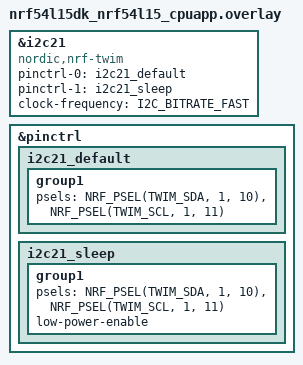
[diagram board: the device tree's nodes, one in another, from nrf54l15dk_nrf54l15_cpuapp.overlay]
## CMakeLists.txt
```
cmake_minimum_required(VERSION 3.20.0)
find_package(Zephyr REQUIRED HINTS $ENV{ZEPHYR_BASE})

project(SCIeval)

target_sources(app PRIVATE
  src/main.c
  src/myble.c
  src/mygpio.c
  src/mysci.c
)

zephyr_library_include_directories(.)
```

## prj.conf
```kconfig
# ==============================
# Logging / Console
# ==============================
CONFIG_LOG=y
CONFIG_LOG_DEFAULT_LEVEL=3

CONFIG_SERIAL=y
CONFIG_UART_CONSOLE=y

# スタック余裕（ログやBLE処理のため）
CONFIG_MAIN_STACK_SIZE=2048
CONFIG_SYSTEM_WORKQUEUE_STACK_SIZE=2048

# ==============================
# Bluetooth (Peripheral/Server)
# ==============================
CONFIG_BT=y
CONFIG_BT_PERIPHERAL=y
# CONFIG_BT_GATT_SERVER は存在しないため指定不要（Peripheralで自動的にGATTサーバ有効）

# デバイス名（Central側が検索する名前に合わせる）
CONFIG_BT_DEVICE_NAME="0514_Test_peripheral"
CONFIG_BT_DEVICE_APPEARANCE=0

# 接続数（必要に応じて調整）
CONFIG_BT_MAX_CONN=1
CONFIG_BT_MAX_PAIRED=1

# ==============================
# PHY / Data Length / MTU
# ==============================
# 2M PHY（ホスト側手続きとコントローラの2M対応）
CONFIG_BT_PHY_UPDATE=y
CONFIG_BT_CTLR_PHY_2M=y

# Data Length Update（bt_conn_le_data_len_update() を使う）
CONFIG_BT_DATA_LEN_UPDATE=y

# ATT MTU（L2CAP TX MTUはMTUに依存）
CONFIG_BT_ATT_PREPARE_COUNT=0
CONFIG_BT_L2CAP_TX_MTU=247

# ACLバッファはデフォルトを使用する
# ※以下のようなシンボルは環境によって未定義のため設定しない
# CONFIG_BT_BUF_ACL_TX_SIZE=
# CONFIG_BT_BUF_ACL_RX_SIZE=
# CONFIG_BT_BUF_ACL_TX_COUNT=
# CONFIG_BT_BUF_ACL_RX_COUNT=

# ==============================
# Nordic LED Button Service (LBS)
# ==============================
CONFIG_BT_LBS=y

# ==============================
# Security（任意）
# ==============================
CONFIG_BT_SMP=n

# ==============================
# その他（必要に応じて）
# ==============================
# GPIOドライバ等はボード定義で有効になっています
```

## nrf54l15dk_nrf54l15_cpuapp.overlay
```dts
/* I2C設定: TWIM21を使用（UART20との競合回避） */

&i2c21 {
    status = "okay";
    compatible = "nordic,nrf-twim";
    pinctrl-0 = <&i2c21_default>;
    pinctrl-1 = <&i2c21_sleep>;
    pinctrl-names = "default", "sleep";
    //clock-frequency = <I2C_BITRATE_STANDARD>; /* 100kHz */
    clock-frequency = <I2C_BITRATE_FAST>; /* 400kHz */
    //clock-frequency = <I2C_BITRATE_FAST_PLUS>; /* 1MHz */
};

&pinctrl {
    i2c21_default: i2c21_default {
        group1 {
            psels = <NRF_PSEL(TWIM_SDA, 1, 10)>,
                    <NRF_PSEL(TWIM_SCL, 1, 11)>;
            //bias-pull-up;  /* ★ 内蔵プルアップを有効化 */
        };
    };

    i2c21_sleep: i2c21_sleep {
        group1 {
            psels = <NRF_PSEL(TWIM_SDA, 1, 10)>,
                    <NRF_PSEL(TWIM_SCL, 1, 11)>;
            low-power-enable;
            //bias-pull-up;  /* ★ スリープ時もプルアップを維持 */
        };
    };
};
```

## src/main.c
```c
#include <zephyr/kernel.h>
#include <zephyr/sys/util.h>
#include <zephyr/sys/atomic.h>
#include <zephyr/logging/log.h>
#include <zephyr/bluetooth/bluetooth.h>
#include <zephyr/bluetooth/conn.h>
#include <zephyr/bluetooth/hci.h>
#include <zephyr/bluetooth/gatt.h>
#include <bluetooth/services/lbs.h>
#include <stdio.h>
#include <string.h>

#include "mygpio.h"
#include "myble.h"
#include "mysci.h"

#define DK //DK or XIAO

LOG_MODULE_REGISTER(blinky, LOG_LEVEL_INF);

#define RUN_LED_BLINK_INTERVAL 1000

/* ======== BTN2押下状態（mygpio.c から更新される） ======== */
atomic_t btn2_pressed_atomic = ATOMIC_INIT(0);

/* ======== カスタムGATT（Notifyで1バイト値を送る） ======== */
/* 任意の128-bit Vendor UUID（アプリ側と合わせればOK） */
static struct bt_uuid_128 casio_svc_uuid = BT_UUID_INIT_128(
    0xF0,0xDE,0xBC,0x9A,0x78,0x56,0x34,0x12,0x34,0x12,0x78,0x56,0x34,0x12,0x56,0x12);
static struct bt_uuid_128 casio_chr_uuid = BT_UUID_INIT_128(
    0xF1,0xDE,0xBC,0x9A,0x78,0x56,0x34,0x12,0x34,0x12,0x78,0x56,0x34,0x12,0x56,0x12);

static uint8_t casio_last_value = 0;
static uint8_t casio_notify_enabled = 0;

/* 送信完了のバックプレッシャ制御（1本インフライト） */
static K_SEM_DEFINE(notify_sem, 1, 1);
static struct bt_gatt_notify_params casio_notify_params;

static void casio_ccc_cfg_changed(const struct bt_gatt_attr *attr, uint16_t value) {
    casio_notify_enabled = (value == BT_GATT_CCC_NOTIFY) ? 1 : 0;
}

static ssize_t casio_read(struct bt_conn *conn, const struct bt_gatt_attr *attr,
                          void *buf, uint16_t len, uint16_t offset) {
    const uint8_t *val = &casio_last_value;
    return bt_gatt_attr_read(conn, attr, buf, len, offset, val, sizeof(*val));
}

/* 静的サービス定義: [0]=Primary, [1]=Char Decl, [2]=Char Value, [3]=CCC */
BT_GATT_SERVICE_DEFINE(casio_svc,
    BT_GATT_PRIMARY_SERVICE(&casio_svc_uuid),
    BT_GATT_CHARACTERISTIC(&casio_chr_uuid.uuid,
        BT_GATT_CHRC_READ | BT_GATT_CHRC_NOTIFY,
        BT_GATT_PERM_READ, casio_read, NULL, &casio_last_value),
    BT_GATT_CCC(casio_ccc_cfg_changed, BT_GATT_PERM_READ | BT_GATT_PERM_WRITE)
);

/* ======== 周期送信ワーク（BTN2押下中のみ送信） ======== */
#define BTN2_TX_INTERVAL_MS 1
static struct k_work_delayable btn2_stream_work;

/* notify 完了コールバック：セマフォを返し、押下中は即次弾を起動 */
static void notify_complete_cb(struct bt_conn *conn, void *user_data)
{
    ARG_UNUSED(conn);
    ARG_UNUSED(user_data);
    k_sem_give(&notify_sem);

    if (atomic_get(&btn2_pressed_atomic) && ble_ready && (my_conn != NULL) && casio_notify_enabled) {
        /* 可能であれば次の送信を即実行（遅延を最小化） */
        k_work_reschedule(&btn2_stream_work, K_NO_WAIT);
    }
}

/* 値を通知する（1本だけインフライト許可） */
static int casio_notify_u8(uint8_t v) {
    if (!ble_ready || my_conn == NULL || !casio_notify_enabled) {
        return -EAGAIN;
    }

    /* インフライトがある場合はスキップ（次のタイミングへ） */
    if (k_sem_take(&notify_sem, K_NO_WAIT) != 0) {
        return -EAGAIN;
    }

    casio_last_value = v;

    memset(&casio_notify_params, 0, sizeof(casio_notify_params));
    casio_notify_params.attr = &casio_svc.attrs[2]; /* Characteristic Value */
    casio_notify_params.data = &casio_last_value;
    casio_notify_params.len  = sizeof(casio_last_value);
    casio_notify_params.func = notify_complete_cb;

    int err = bt_gatt_notify_cb(my_conn, &casio_notify_params);
    if (err) {
        /* 送信失敗時はセマフォを返却しておく */
        k_sem_give(&notify_sem);
    }
    return err;
}

static void btn2_stream_work_handler(struct k_work *work) {
    ARG_UNUSED(work);
    static uint8_t counter = 0;
    static bool prev_pressed = false;

    bool pressed = (atomic_get(&btn2_pressed_atomic) != 0);

    /* 押下/解放のエッジで SCI のモードを切り替える */
    if (pressed && !prev_pressed) {
        /* 低遅延モード（1～4ms を許容範囲として要求） */
        mysci_set_mode(MYSCI_MODE_LOW_LATENCY);
    } else if (!pressed && prev_pressed) {
        /* バランスモード（4～10ms を許容範囲として要求） */
        mysci_set_mode(MYSCI_MODE_BALANCED);
    }
    prev_pressed = pressed;

    /* 押下中かつ接続＆Notify有効なら送信 */
    if (pressed && ble_ready && (my_conn != NULL) && casio_notify_enabled) {
        int err = casio_notify_u8(counter);
        if (err && err != -EAGAIN) {
            LOG_DBG("notify err=%d", err);
        }
        counter++; /* 自動で 0→255→0 と回る */
    }

    /* 保険として 1ms 後に再チェック（送信完了時は即時再スケジュールが入る） */
    k_work_schedule(&btn2_stream_work, K_MSEC(BTN2_TX_INTERVAL_MS));
}

/* ------------------------- main ------------------------- */
int main(void) {
    int err;
    LOG_INF("Main loop\n");

    /* gpio initialize */
    err = gpio_init_all();
    if (err) {
        LOG_ERR("GPIO init failed (err %d)", err);
        return -1;
    }

    pin_set_logic(LED0, true);

    /* BLE スタック起動 */
    err = bt_enable(NULL);
    if (err) {
        LOG_ERR("Bluetooth init failed (err %d)", err);
        return -1;
    }
    ble_ready = true;
    LOG_INF("Bluetooth initialized");

    /* SCI 初期化（デフォルト許容レンジの設定、コールバック登録など） */
    mysci_init();

    /* LBS サービス初期化 */
    const struct bt_lbs_cb lbs_cb = {
        .led_cb = lbs_led_cb,
    };
    err = bt_lbs_init(&lbs_cb);
    if (err) {
        LOG_ERR("bt_lbs_init failed (err %d)", err);
        return -1;
    }
    lbs_ready = true;

    pin_set_logic(LED0, false);

    /* コネクションコールバック登録とアドバタイズ開始 */
    err = bt_conn_cb_register(&connection_callbacks);
    if (err) {
        LOG_ERR("Connection callback register failed (err %d)", err);
    }

    k_work_init(&adv_work, adv_work_handler);
    advertising_start();

    #ifdef DK
    /* 周期送信ワーク開始（1msごと、押下中のみ送信＋SCI制御） */
    k_work_init_delayable(&btn2_stream_work, btn2_stream_work_handler);
    k_work_schedule(&btn2_stream_work, K_MSEC(BTN2_TX_INTERVAL_MS));
    #endif

    /* BLE/LBS 準備完了後に、ボタン割り込みを有効化 */
    err = gpio_enable_button_irq();
    if (err) {
        LOG_ERR("Enable button IRQ failed (err %d)", err);
        return -1;
    }

    pin_set_logic(LED0, true);

    /* main loop */
    for (;;) {
        k_sleep(K_SECONDS(1));
    }
}
```

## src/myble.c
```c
#include "myble.h"
#include "mygpio.h"

#include <zephyr/kernel.h>
#include <zephyr/sys/util.h>
#include <zephyr/logging/log.h>

#include <zephyr/bluetooth/bluetooth.h>
#include <zephyr/bluetooth/gap.h>
#include <zephyr/bluetooth/gatt.h>
#include <zephyr/bluetooth/uuid.h>
#include <zephyr/bluetooth/addr.h>
#include <zephyr/bluetooth/conn.h>
#include <bluetooth/services/lbs.h>

LOG_MODULE_REGISTER(myble, LOG_LEVEL_INF);

/* ------------------------- BLE/Advertising ------------------------- */
struct bt_conn *my_conn = NULL;
struct k_work adv_work;
bool ble_ready = false;
bool lbs_ready = false;

static const struct bt_le_adv_param *adv_param = BT_LE_ADV_PARAM(
    (BT_LE_ADV_OPT_CONN | BT_LE_ADV_OPT_USE_IDENTITY),
    BT_GAP_ADV_FAST_INT_MIN_1,
    BT_GAP_ADV_FAST_INT_MAX_1,
    NULL);

static const struct bt_data ad[] = {
    BT_DATA_BYTES(BT_DATA_FLAGS, (BT_LE_AD_GENERAL | BT_LE_AD_NO_BREDR)),
    BT_DATA(BT_DATA_NAME_COMPLETE, CONFIG_BT_DEVICE_NAME, (sizeof(CONFIG_BT_DEVICE_NAME) - 1)),
};

static const struct bt_data sd[] = {
    BT_DATA_BYTES(BT_DATA_UUID128_ALL,
                  BT_UUID_128_ENCODE(0x00001523, 0x1212, 0xefde, 0x1523, 0x785feabcd123)),
};

void adv_work_handler(struct k_work *work){
    ARG_UNUSED(work);
    int err = bt_le_adv_start(adv_param, ad, ARRAY_SIZE(ad), sd, ARRAY_SIZE(sd));
    if (err) {
        LOG_ERR("Advertising failed to start (err %d)", err);
        return;
    }
    LOG_INF("Advertising successfully started");
}

void advertising_start(void){
    k_work_submit(&adv_work);
}

/* ------------------------- BLE ユーティリティ ------------------------- */
static struct bt_gatt_exchange_params exchange_params;

static void update_phy(struct bt_conn *conn){
    int err;
    const struct bt_conn_le_phy_param preferred_phy = {
        .options = BT_CONN_LE_PHY_OPT_NONE,
        .pref_rx_phy = BT_GAP_LE_PHY_2M,
        .pref_tx_phy = BT_GAP_LE_PHY_2M,
    };
    err = bt_conn_le_phy_update(conn, &preferred_phy);
    if (err) {
        LOG_ERR("bt_conn_le_phy_update() returned %d", err);
    }
}

static void update_data_length(struct bt_conn *conn){
    int err;
    struct bt_conn_le_data_len_param my_data_len = {
        .tx_max_len = BT_GAP_DATA_LEN_MAX,
        .tx_max_time = BT_GAP_DATA_TIME_MAX,
    };
    err = bt_conn_le_data_len_update(conn, &my_data_len);
    if (err) {
        LOG_ERR("data_len_update failed (err %d)", err);
    }
}

static void exchange_func(struct bt_conn *conn, uint8_t att_err, struct bt_gatt_exchange_params *params){
    ARG_UNUSED(params);
    LOG_INF("MTU exchange %s", att_err == 0 ? "successful" : "failed");
    if (!att_err) {
        uint16_t payload_mtu = bt_gatt_get_mtu(conn) - 3;   /* 3 bytes for ATT header */
        LOG_INF("New MTU: %d bytes", payload_mtu);
    }
}

static void update_mtu(struct bt_conn *conn){
    int err;
    exchange_params.func = exchange_func;

    err = bt_gatt_exchange_mtu(conn, &exchange_params);
    if (err) {
        LOG_ERR("bt_gatt_exchange_mtu failed (err %d)", err);
    }
}

static void update_conn_params(struct bt_conn *conn){
    struct bt_le_conn_param param = {
        .interval_min = 6,   /* 6 * 1.25ms = 7.5ms */
        .interval_max = 6,   /* 固定要求 */
        .latency      = 0,
        .timeout      = 400, /* 4s */
    };
    int err = bt_conn_le_param_update(conn, &param);
    if (err) {
        LOG_ERR("bt_conn_le_param_update failed (err %d)", err);
    } else {
        LOG_INF("Requested connection params: 7.5ms, latency 0, timeout 4s");
    }
}

/* ------------------------- LBS 初期化（main から渡されるコールバック） ------------------------- */
void lbs_led_cb(bool led_state){
    /* 必要に応じて LED 連動 */
    ARG_UNUSED(led_state);
}

/* ------------------------- BLE コールバック ------------------------- */
static void on_connected(struct bt_conn *conn, uint8_t err){
    if (err) {
        LOG_ERR("Connection error %d", err);
        return;
    }
    LOG_INF("Connected");
    my_conn = bt_conn_ref(conn);

    /* 接続 LED ON */
    pin_set_logic(LED2, true);
    k_sleep(K_MSEC(100));

    struct bt_conn_info info;
    err = bt_conn_get_info(conn, &info);
    if (err) {
        LOG_ERR("bt_conn_get_info() returned %d", err);
        return;
    }

    double connection_interval = BT_GAP_US_TO_CONN_INTERVAL(info.le.interval_us) * 1.25; /* ms */
    uint16_t supervision_timeout = info.le.timeout * 10; /* ms */
    LOG_INF("Connection parameters: interval %.2f ms, latency %d intervals, timeout %d ms",
            connection_interval, info.le.latency, supervision_timeout);

    /* 低遅延化リクエスト */
    update_conn_params(conn);   /* 7.5ms を要求 */
    update_phy(conn);           /* 2M PHY を要求 */
    update_data_length(conn);   /* Data Length Extension */
    update_mtu(conn);           /* ATT MTU 交換 */
}

static void on_disconnected(struct bt_conn *conn, uint8_t reason){
    ARG_UNUSED(conn);
    LOG_INF("Disconnected. Reason %d", reason);
    /* 接続 LED OFF */
    pin_set_logic(LED2, false);
    if (my_conn) {
        bt_conn_unref(my_conn);
        my_conn = NULL;
    }
}

static void on_recycled(void){
    advertising_start();
}

static void on_le_param_updated(struct bt_conn *conn, uint16_t interval, uint16_t latency, uint16_t timeout){
    ARG_UNUSED(conn);
    double connection_interval = interval * 1.25;         /* ms */
    uint16_t supervision_timeout = timeout * 10;          /* ms */
    LOG_INF("Connection parameters updated: interval %.2f ms, latency %d intervals, timeout %d ms",
            connection_interval, latency, supervision_timeout);
}

static void on_le_phy_updated(struct bt_conn *conn, struct bt_conn_le_phy_info *param){
    ARG_UNUSED(conn);
    switch (param->tx_phy) {
    case BT_GAP_LE_PHY_1M:
        LOG_INF("PHY updated. New PHY: 1M");
        break;
    case BT_GAP_LE_PHY_2M:
        LOG_INF("PHY updated. New PHY: 2M");
        break;
    case BT_GAP_LE_PHY_CODED:
        LOG_INF("PHY updated. New PHY: Coded");
        break;
    default:
        LOG_INF("PHY updated. New PHY: 0x%02x", param->tx_phy);
        break;
    }
}

static void on_le_data_len_updated(struct bt_conn *conn, struct bt_conn_le_data_len_info *info){
    ARG_UNUSED(conn);
    uint16_t tx_len  = info->tx_max_len;
    uint16_t tx_time = info->tx_max_time;
    uint16_t rx_len  = info->rx_max_len;
    uint16_t rx_time = info->rx_max_time;
    LOG_INF("Data length updated. Length %d/%d bytes, time %d/%d us", tx_len, rx_len, tx_time, rx_time);
}

struct bt_conn_cb connection_callbacks = {
    .connected            = on_connected,
    .disconnected         = on_disconnected,
    .recycled             = on_recycled,
    .le_param_updated     = on_le_param_updated,
    .le_phy_updated       = on_le_phy_updated,
    .le_data_len_updated  = on_le_data_len_updated,
};
```

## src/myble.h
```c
#ifndef MYBLE_H_
#define MYBLE_H_

#ifdef __cplusplus
extern "C" {
#endif

#include <stdbool.h>

/* 前方宣言（ヘッダで重い Zephyr ヘッダを引き込まないため） */
struct k_work;
struct bt_conn_cb;
struct bt_conn;

/* main / mygpio から参照する BLE 状態 */
extern struct bt_conn *my_conn;
extern bool ble_ready;
extern bool lbs_ready;

/* main から直接使うアドバタイズ関連オブジェクト */
extern struct k_work adv_work;
void adv_work_handler(struct k_work *work);
void advertising_start(void);

/* main から登録するコネクションコールバック */
extern struct bt_conn_cb connection_callbacks;

/* LBS の LED 書き込みコールバック（main から渡す） */
void lbs_led_cb(bool led_state);


#ifdef __cplusplus
}
#endif

#endif /* MYBLE_H */
```

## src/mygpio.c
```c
#include "mygpio.h"
#include "myble.h"

#include <zephyr/kernel.h>
#include <zephyr/sys/atomic.h>
#include <zephyr/logging/log.h>
#include <zephyr/drivers/gpio.h>
#include <bluetooth/services/lbs.h>

/* このモジュールのログ名 */
LOG_MODULE_REGISTER(mygpio, LOG_LEVEL_INF);

/* 他ファイル（main.c）で定義しているBTN2押下フラグ */
extern atomic_t btn2_pressed_atomic;

/* ------------------------- GPIO 設定 ------------------------- */
#define DEV_GPIO0 DEVICE_DT_GET(DT_NODELABEL(gpio0)) /* P0.x */
#define DEV_GPIO1 DEVICE_DT_GET(DT_NODELABEL(gpio1)) /* P1.x */
#define DEV_GPIO2 DEVICE_DT_GET(DT_NODELABEL(gpio2)) /* P2.x */

#define DK //DK or XIAO

typedef struct {
    const struct device *port; /* 例: DEV_GPIO1/DEV_GPIO2 */
    uint8_t pin;               /* Px.y の y 部分 */
    bool is_output;            /* 出力なら true, 入力なら false */
    bool active_low;           /* 論理 ON を物理 Low で表すなら true */
    bool pull_up;              /* 入力時: プルアップ使用なら true */
    bool use_irq;              /* 入力時: 割り込み使用なら true */
} pin_cfg_t;

// しばらくは dk で開発
static const pin_cfg_t pins[PIN_COUNT] = {
    // for dk
    #ifdef DK
    [LED0] = { .port = DEV_GPIO2, .pin = 9,  .is_output = true,  .active_low = false, .pull_up = false, .use_irq = false }, /* P2.09 */
    [LED1] = { .port = DEV_GPIO1, .pin = 10, .is_output = true,  .active_low = false, .pull_up = false, .use_irq = false }, /* P1.10 */
    [LED2] = { .port = DEV_GPIO2, .pin = 7,  .is_output = true,  .active_low = false, .pull_up = false, .use_irq = false }, /* P2.07 */
    [LED3] = { .port = DEV_GPIO1, .pin = 14, .is_output = true,  .active_low = false, .pull_up = false, .use_irq = false }, /* P1.14 */
    [BTN0] = { .port = DEV_GPIO1, .pin = 13, .is_output = false, .active_low = true,  .pull_up = true,  .use_irq = true  }, /* P1.13 (押下=Low) */
    [BTN1] = { .port = DEV_GPIO1, .pin = 9,  .is_output = false, .active_low = true,  .pull_up = true,  .use_irq = true  }, /* P1.09 (押下=Low) */
    [BTN2] = { .port = DEV_GPIO1, .pin = 8,  .is_output = false, .active_low = true,  .pull_up = true,  .use_irq = true  }, /* P1.08 (押下=Low) */
    [BTN3] = { .port = DEV_GPIO0, .pin = 4,  .is_output = false, .active_low = true,  .pull_up = true,  .use_irq = true  }, /* P0.04 (押下=Low) */
    #endif
    //for xiao
    #ifdef XIAO
    [BTN0] = { .port = DEV_GPIO0, .pin = 0, .is_output = false, .active_low = true,  .pull_up = true,  .use_irq = true  }, /* P0.00 (押下=Low) */
    [LED0] = { .port = DEV_GPIO2, .pin = 0,  .is_output = true,  .active_low = false, .pull_up = false, .use_irq = false }, /* P2.00 */
    #endif
};

/* 論理 ON/OFF をアクティブ極性に従って出力するヘルパ */
int pin_set_logic(pin_id_t id, bool on){
    const pin_cfg_t *c = &pins[id];
    if (!c->is_output) {
        return -EINVAL;
    }
    int level = c->active_low ? !on : on;
    return gpio_pin_set(c->port, c->pin, level);
}

/* 入力/出力の論理値を取得（active_low を吸収） */
static bool pin_get_logic(pin_id_t id){
    const pin_cfg_t *c = &pins[id];
    int v = gpio_pin_get(c->port, c->pin);
    if (v < 0) {
        return false; /* 読み取り失敗時は false 扱い */
    }
    return c->active_low ? (v == 0) : (v == 1);
}

/* ------------------------- ボタンイベント（ワークキュー処理） ------------------------- */
static struct gpio_callback btn_cb;
static struct k_work button_work;   /* BTN0 -> LBS通知 */
static struct k_work btn1_work;     /* BTN1 -> LED3トグル */
static struct k_work btn2_work;     /* BTN2 -> LED1点灯/消灯 + 送信制御 */
static atomic_t btn_state_atomic;

static void button_work_handler(struct k_work *work){
    ARG_UNUSED(work);
    /* BLE/LBS 準備完了かつ接続済みのときだけ通知を送る */
    if (!ble_ready || !lbs_ready || (my_conn == NULL)) {
        return;
    }
    bool pressed = (atomic_get(&btn_state_atomic) != 0);
    int err = bt_lbs_send_button_state(pressed);
    if (err) {
        LOG_ERR("Couldn't send notification. (err: %d)", err);
    }
    LOG_INF("BTN0 %s", pressed ? "pressed" : "released");
}
#ifdef DK
static void btn1_work_handler(struct k_work *work){
    ARG_UNUSED(work);
    /* 押下時のみトグル（active_lowなので論理 ON = 押下） */
    bool pressed = pin_get_logic(BTN1);
    if (!pressed) {
        return;
    }
    bool current = pin_get_logic(LED3);
    pin_set_logic(LED3, !current);
    LOG_INF("BTN1 pressed: LED3 -> %s", (!current) ? "ON" : "OFF");
}


static void btn2_work_handler(struct k_work *work){
    ARG_UNUSED(work);
    /* 押下（active_lowなので論理 ON）でLED1点灯・送信開始、解放で消灯・送信停止 */
    bool pressed = pin_get_logic(BTN2);
    if (!pressed) {
        pin_set_logic(LED1, false);
        atomic_set(&btn2_pressed_atomic, 0);
        LOG_INF("BTN2 released: LED1 -> OFF");
    } else {
        pin_set_logic(LED1, true);
        atomic_set(&btn2_pressed_atomic, 1);
        LOG_INF("BTN2 pressed: LED1 -> ON");
    }
}
#endif

static void button_isr(const struct device *port, struct gpio_callback *cb, uint32_t pins_mask){
    ARG_UNUSED(cb);

    /* BTN0イベント: 押下/解放でLBS通知 */
    if ((port == pins[BTN0].port) && (pins_mask & BIT(pins[BTN0].pin))) {
        bool pressed0 = pin_get_logic(BTN0); /* 論理 ON = 押下 */
        atomic_set(&btn_state_atomic, pressed0 ? 1 : 0);
        k_work_submit(&button_work);
    }

    #ifdef DK
    /* BTN1イベント: 押下でLED3をトグル */
    if ((port == pins[BTN1].port) && (pins_mask & BIT(pins[BTN1].pin))) {
        /* トグルはワークキューで実施 */
        k_work_submit(&btn1_work);
    }

    /* BTN2イベント: 押下/解放でLED1制御＋送信制御 */
    if ((port == pins[BTN2].port) && (pins_mask & BIT(pins[BTN2].pin))) {
        k_work_submit(&btn2_work);
    }
    #endif
}

/* 起動時は割り込みを有効化しない。BLE/LBS 初期化後に有効化する */
int gpio_enable_button_irq(void){
    int err;

    /* BTN0: 押下/解放の両エッジで通知 */
    err = gpio_pin_interrupt_configure(pins[BTN0].port, pins[BTN0].pin, GPIO_INT_EDGE_BOTH);
    if (err) {
        LOG_ERR("Interrupt config for BTN0 failed (%d)", err);
        return err;
    }

    #ifdef DK
    /* BTN1: 押下（立下り）でLEDトグル */
    err = gpio_pin_interrupt_configure(pins[BTN1].port, pins[BTN1].pin, GPIO_INT_EDGE_FALLING);
    if (err) {
        LOG_ERR("Interrupt config for BTN1 failed (%d)", err);
        return err;
    }

    /* BTN2: 押下/解放の両エッジでLED制御＋送信制御 */
    err = gpio_pin_interrupt_configure(pins[BTN2].port, pins[BTN2].pin, GPIO_INT_EDGE_BOTH);
    if (err) {
        LOG_ERR("Interrupt config for BTN2 failed (%d)", err);
        return err;
    }

    /* 同一ポート(P1)の BTN0/BTN1/BTN2 をひとつのコールバックで受ける */
    gpio_init_callback(&btn_cb, button_isr, BIT(pins[BTN0].pin) | BIT(pins[BTN1].pin) | BIT(pins[BTN2].pin));
    gpio_add_callback(pins[BTN0].port, &btn_cb);
    #endif

    #ifdef XIAO
    /* 同一ポート(P1)の BTN0 をひとつのコールバックで受ける */
    gpio_init_callback(&btn_cb, button_isr, BIT(pins[BTN0].pin));
    gpio_add_callback(pins[BTN0].port, &btn_cb);
    #endif

    return 0;
}

int gpio_init_all(void){
    /* すべての使用ポートの ready チェック */
    for (int i = 0; i < PIN_COUNT; i++) {
        if (!device_is_ready(pins[i].port)) {
            LOG_ERR("GPIO port not ready for pin index %d", i);
            return -ENODEV;
        }
    }

    /* ピンを一括設定 */
    for (int i = 0; i < PIN_COUNT; i++) {
        const pin_cfg_t *c = &pins[i];
        int err;
        if (c->is_output) {
            err = gpio_pin_configure(c->port, c->pin, GPIO_OUTPUT_INACTIVE);
            if (err) {
                LOG_ERR("Configure output pin %d failed (%d)", i, err);
                return err;
            }
        } else {
            gpio_flags_t flags = GPIO_INPUT | (c->pull_up ? GPIO_PULL_UP : 0);
            err = gpio_pin_configure(c->port, c->pin, flags);
            if (err) {
                LOG_ERR("Configure input pin %d failed (%d)", i, err);
                return err;
            }
            /* 割り込みはここでは有効化しない（BLE/LBS 初期化後に有効化） */
        }
    }

    /* ボタンワーク初期化 */
    k_work_init(&button_work, button_work_handler);
    #ifdef DK
    k_work_init(&btn1_work, btn1_work_handler);
    k_work_init(&btn2_work, btn2_work_handler);
    #endif

    return 0;
}
```

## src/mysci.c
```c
#include "mysci.h"
#include "myble.h"

#include <zephyr/kernel.h>
#include <zephyr/logging/log.h>
#include <zephyr/sys/util.h>
#include <zephyr/bluetooth/bluetooth.h>
#include <zephyr/bluetooth/conn.h>
#include <zephyr/bluetooth/hci.h>

LOG_MODULE_REGISTER(mysci, LOG_LEVEL_INF);

/* セマフォ（PHY/IFS の更新完了待ち） */
static K_SEM_DEFINE(phy_updated_sem, 0, 1);
static K_SEM_DEFINE(frame_space_updated_sem, 0, 1);

/* ローカルでサポートされる最小接続間隔(µs)を保持 */
static uint16_t local_min_interval_us = 1000;

/* 現在/希望モード */
static mysci_mode_t desired_mode = MYSCI_MODE_BALANCED;

/* 接続後にSCIシーケンスを実施するワーク */
static struct k_work_delayable sci_start_work;

/* 内部ヘルパ */
static inline uint16_t us_to_125us(uint32_t us) { return (uint16_t)(us / 125); }

/* IFS更新: 2M PHY, ACL IFS を最小化 */
static int sci_select_lowest_frame_space(struct bt_conn *conn)
{
    const struct bt_conn_le_frame_space_update_param params = {
        .phys = BT_HCI_LE_FRAME_SPACE_UPDATE_PHY_2M_MASK,
        .spacing_types = BT_CONN_LE_FRAME_SPACE_TYPES_MASK_ACL_IFS,
        .frame_space_min = 0,
        .frame_space_max = 150, /* us */
    };

    int err = bt_conn_le_frame_space_update(conn, &params);
    if (err) {
        LOG_WRN("frame_space_update failed (err %d)", err);
        return err;
    }

    if (k_sem_take(&frame_space_updated_sem, K_MSEC(1500)) != 0) {
        LOG_WRN("frame_space_update timeout");
        return -ETIMEDOUT;
    }
    return 0;
}

/* 2M PHYへ更新 */
static int sci_update_to_2m_phy(struct bt_conn *conn)
{
    const struct bt_conn_le_phy_param phy = {
        .options = BT_CONN_LE_PHY_OPT_NONE,
        .pref_rx_phy = BT_GAP_LE_PHY_2M,
        .pref_tx_phy = BT_GAP_LE_PHY_2M,
    };
    int err = bt_conn_le_phy_update(conn, &phy);
    if (err) {
        LOG_WRN("phy_update failed (err %d)", err);
        return err;
    }
    if (k_sem_take(&phy_updated_sem, K_MSEC(1500)) != 0) {
        LOG_WRN("phy_update timeout");
        return -ETIMEDOUT;
    }
    return 0;
}

/* SCIリクエストを投げる（モード別の min/max を組み立て） */
static int sci_request_mode(struct bt_conn *conn, mysci_mode_t mode)
{
    uint32_t min_us;
    uint32_t max_us;

    switch (mode) {
    case MYSCI_MODE_LOW_LATENCY:
        /* 最短はローカル最小値と 1ms の大きい方、上限は 4ms */
        min_us = MAX((uint32_t)local_min_interval_us, (uint32_t)1000);
        max_us = 4000;
        break;
    case MYSCI_MODE_BALANCED:
    default:
        /* 下限は 4ms 以上（ローカル制約を満たす）、上限は 10ms */
        min_us = MAX((uint32_t)local_min_interval_us, (uint32_t)4000);
        max_us = 10000;
        break;
    }

    if (min_us > max_us) {
        /* 端末制約が厳しすぎる場合のフォールバック */
        min_us = max_us;
    }

    const struct bt_conn_le_conn_rate_param params = {
        .interval_min_125us = us_to_125us(min_us),
        .interval_max_125us = us_to_125us(max_us),
        .subrate_min = 1,
        .subrate_max = 1,
        .max_latency = 0, /* peripheral latency = 0 (スキップなし) */
        .continuation_number = 0,
        .supervision_timeout_10ms = 400, /* 4s */
        .min_ce_len_125us = BT_HCI_LE_SCI_CE_LEN_MIN_125US,
        .max_ce_len_125us = BT_HCI_LE_SCI_CE_LEN_MAX_125US,
    };

    int err = bt_conn_le_conn_rate_request(conn, &params);
    if (err) {
        LOG_WRN("conn_rate_request failed (err %d), range=%u..%u us",
                err, (unsigned)min_us, (unsigned)max_us);
        return err;
    }
    LOG_INF("SCI requested: %u..%u us (mode=%d)", (unsigned)min_us, (unsigned)max_us, mode);
    return 0;
}

/* 接続後の一連のSCI手順を実行（ワークハンドラ） */
static void sci_start_work_handler(struct k_work *work)
{
    ARG_UNUSED(work);
    if (my_conn == NULL) {
        return;
    }

    /* ローカル最小接続間隔（µs）を取得 */
    int err = bt_conn_le_read_min_conn_interval(&local_min_interval_us);
    if (err) {
        LOG_WRN("read_min_conn_interval failed (err %d). Fallback to 1000us", err);
        local_min_interval_us = 1000;
    }
    LOG_INF("Local min conn interval: %u us", local_min_interval_us);

    /* 2M PHY へ */
    err = sci_update_to_2m_phy(my_conn);
    if (err) {
        LOG_WRN("2M PHY setup failed (err %d)", err);
        /* 失敗しても続行（環境によっては1Mのまま） */
    }

    /* ACL IFS を可能な限り縮小 */
    err = sci_select_lowest_frame_space(my_conn);
    if (err) {
        LOG_WRN("Frame space update failed (err %d)", err);
    }

    /* 直近の希望モードで SCI を要求 */
    sci_request_mode(my_conn, desired_mode);
}

/* ===== コールバック ===== */
static bool le_param_req(struct bt_conn *conn, struct bt_le_conn_param *param)
{
    ARG_UNUSED(conn);
    ARG_UNUSED(param);
    /* 旧来のパラメータ更新（Peer起点）は不採用にしてSCI更新で統一 */
    return false;
}

static void le_phy_updated_cb(struct bt_conn *conn, struct bt_conn_le_phy_info *param)
{
    ARG_UNUSED(conn);
    LOG_INF("PHY updated: TX %u, RX %u", param->tx_phy, param->rx_phy);
    k_sem_give(&phy_updated_sem);
}

static void frame_space_updated_cb(struct bt_conn *conn,
                                   const struct bt_conn_le_frame_space_updated *params)
{
    if (params->status == BT_HCI_ERR_SUCCESS) {
        LOG_INF("Frame space updated: %u us, phys=0x%02x, types=0x%04x",
                params->frame_space, params->phys, params->spacing_types);
    } else {
        LOG_WRN("Frame space update failed: 0x%02x", params->status);
    }
    k_sem_give(&frame_space_updated_sem);
}

static void conn_rate_changed_cb(struct bt_conn *conn, uint8_t status,
                                 const struct bt_conn_le_conn_rate_changed *params)
{
    if (status == BT_HCI_ERR_SUCCESS) {
        LOG_INF("SCI applied: interval %u us, subrate %d, periph_latency %d, cont %d, sup_to %d ms",
                params->interval_us, params->subrate_factor, params->peripheral_latency,
                params->continuation_number, params->supervision_timeout_10ms * 10);
    } else {
        LOG_WRN("SCI change failed: 0x%02x", status);
    }
}

static void connected_cb(struct bt_conn *conn, uint8_t err)
{
    if (err) {
        return;
    }
    /* 接続直後のSCIシーケンスを少し遅延して開始（他セットアップ後に上書きする） */
    k_work_schedule(&sci_start_work, K_MSEC(200));
}

static void disconnected_cb(struct bt_conn *conn, uint8_t reason)
{
    ARG_UNUSED(conn);
    ARG_UNUSED(reason);
    /* 次回接続に備えてワークをキャンセル */
    k_work_cancel_delayable(&sci_start_work);
}

/* このモジュールのコールバック（mybleのものと併用登録OK） */
static struct bt_conn_cb sci_conn_cbs = {
    .connected = connected_cb,
    .disconnected = disconnected_cb,
    .le_param_req = le_param_req,
    .le_phy_updated = le_phy_updated_cb,
    .frame_space_updated = frame_space_updated_cb,
    .conn_rate_changed = conn_rate_changed_cb,
};

/* ===== 公開関数 ===== */
void mysci_init(void)
{
    /* デフォルト許容レンジ（Peripheral側の受入範囲）を広めに設定 */
    uint16_t local_min_us = 1000;
    if (bt_conn_le_read_min_conn_interval(&local_min_us) != 0) {
        local_min_us = 1000;
    }
    const struct bt_conn_le_conn_rate_param defaults = {
        .interval_min_125us = us_to_125us(local_min_us),
        .interval_max_125us = us_to_125us(10000), /* 10ms */
        .subrate_min = 1,
        .subrate_max = 1,
        .max_latency = 5, /* デフォルトは多少許容 */
        .continuation_number = 0,
        .supervision_timeout_10ms = 400,
        .min_ce_len_125us = BT_HCI_LE_SCI_CE_LEN_MIN_125US,
        .max_ce_len_125us = BT_HCI_LE_SCI_CE_LEN_MAX_125US,
    };
    int err = bt_conn_le_conn_rate_set_defaults(&defaults);
    if (err) {
        LOG_WRN("SCI defaults set failed (err %d)", err);
    } else {
        LOG_INF("SCI defaults set: %u..%u us", local_min_us, 10000);
    }

    /* ローカル最小値を保持 */
    local_min_interval_us = local_min_us;

    /* コールバック登録、ワーク初期化 */
    bt_conn_cb_register(&sci_conn_cbs);
    k_work_init_delayable(&sci_start_work, sci_start_work_handler);
}

void mysci_set_mode(mysci_mode_t mode)
{
    desired_mode = mode;

    /* 接続済みなら即時SCIを要求（PHY/IFS前提が未完了でも試みる） */
    if (my_conn) {
        (void)sci_request_mode(my_conn, desired_mode);
    }
}
```

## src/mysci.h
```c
#ifndef MYSCI_H_
#define MYSCI_H_

#ifdef __cplusplus
extern "C" {
#endif

#include <stdbool.h>

/* SCI動作モード */
typedef enum {
    MYSCI_MODE_BALANCED = 0,   /* 4～10ms程度（省電力寄り） */
    MYSCI_MODE_LOW_LATENCY,    /* 1～4ms程度（低遅延） */
} mysci_mode_t;

/* 初期化：SCIデフォルト設定、コールバック登録 */
void mysci_init(void);

/* 動作モード切替（接続中なら即時要求、未接続なら次回接続後に適用） */
void mysci_set_mode(mysci_mode_t mode);

#ifdef __cplusplus
}
#endif

#endif /* MYSCI_H_ */
```
